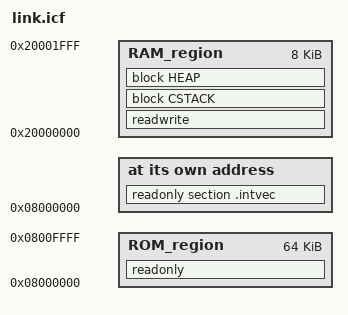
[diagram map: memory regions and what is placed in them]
/*###ICF### Section handled by ICF editor, don't touch! ****/
/*-Editor annotation file-*/
/* IcfEditorFile="$TOOLKIT_DIR$\config\ide\IcfEditor\cortex_v1_0.xml" */
/*-Specials-*/
define symbol __ICFEDIT_intvec_start__ = 0x08000000;
/*-Memory Regions-*/
/*
 * IMPORTANT: Please check your specific chip's datasheet for correct memory sizes.
 * The following values are for a GD32E230 with 64KB Flash and 8KB SRAM.
 */
define symbol __ICFEDIT_region_ROM_start__ = 0x08000000;
define symbol __ICFEDIT_region_ROM_end__   = 0x0800FFFF;  /* 64KB Flash */
define symbol __ICFEDIT_region_RAM_start__ = 0x20000000;
define symbol __ICFEDIT_region_RAM_end__   = 0x20001FFF;  /* 8KB SRAM */
/*-Sizes-*/
/*
 * The CSTACK is used for main function before scheduler start and for interrupt handlers.
 * The HEAP is the C library heap, which is rarely used in RT-Thread.
 * RT-Thread uses the remaining RAM for its own dynamic memory heap.
 */
define symbol __ICFEDIT_size_cstack__ = 0x400;  /* 1024 bytes, a safer size */
define symbol __ICFEDIT_size_heap__   = 0x100;  /* 256 bytes, can be smaller */
/**** End of ICF editor section. ###ICF###*/


define memory mem with size = 4G;
define region ROM_region   = mem:[from __ICFEDIT_region_ROM_start__   to __ICFEDIT_region_ROM_end__];
define region RAM_region   = mem:[from __ICFEDIT_region_RAM_start__   to __ICFEDIT_region_RAM_end__];

/* Remove the non-existent RAM1 region */
/* define region RAM1_region  = mem:[from __region_RAM1_start__   to __region_RAM1_end__]; */


define block CSTACK    with alignment = 8, size = __ICFEDIT_size_cstack__   { };
define block HEAP      with alignment = 8, size = __ICFEDIT_size_heap__     { };

initialize by copy { readwrite };
do not initialize  { section .noinit };

/* Keep RT-Thread FinSH command symbols */
keep { section FSymTab };
keep { section VSymTab };
keep { section .rti_fn* };
place at address mem:__ICFEDIT_intvec_start__ { readonly section .intvec };

place in ROM_region   { readonly };
place in RAM_region   { readwrite,
                        block CSTACK, block HEAP };

/* Remove placement in the non-existent RAM1 region */
/* place in RAM1_region  { section .sram }; */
